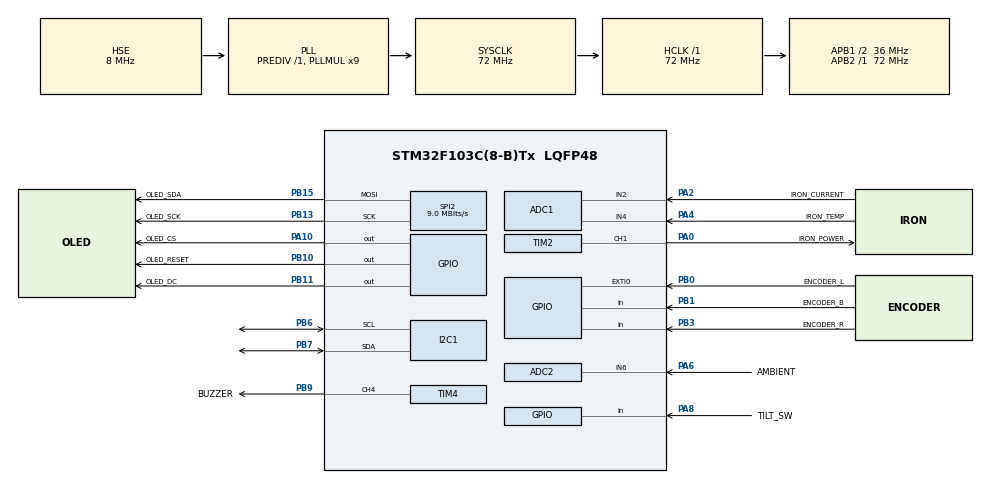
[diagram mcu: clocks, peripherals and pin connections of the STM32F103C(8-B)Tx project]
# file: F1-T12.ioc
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ADC1.Channel-0\#ChannelRegularConversion=ADC_CHANNEL_2
ADC1.Channel-1\#ChannelRegularConversion=ADC_CHANNEL_6
ADC1.ContinuousConvMode=ENABLE
ADC1.Mode=ADC_DUALMODE_INTERLFAST
ADC1.NbrOfConversion=2
ADC1.NbrOfConversionFlag=1
ADC1.Rank-0\#ChannelRegularConversion=1
ADC1.Rank-1\#ChannelRegularConversion=2
ADC1.SamplingTime-0\#ChannelRegularConversion=ADC_SAMPLETIME_71CYCLES_5
ADC1.SamplingTime-1\#ChannelRegularConversion=ADC_SAMPLETIME_71CYCLES_5
ADC1.master=1
ADC2.Channel-0\#ChannelRegularConversion=ADC_CHANNEL_4
ADC2.Channel-1\#ChannelRegularConversion=ADC_CHANNEL_4
ADC2.ContinuousConvMode=ENABLE
ADC2.Mode=ADC_DUALMODE_INTERLFAST
ADC2.NbrOfConversion=2
ADC2.NbrOfConversionFlag=1
ADC2.Rank-0\#ChannelRegularConversion=1
ADC2.Rank-1\#ChannelRegularConversion=2
ADC2.SamplingTime-0\#ChannelRegularConversion=ADC_SAMPLETIME_71CYCLES_5
ADC2.SamplingTime-1\#ChannelRegularConversion=ADC_SAMPLETIME_71CYCLES_5
Dma.ADC1.0.Direction=DMA_PERIPH_TO_MEMORY
Dma.ADC1.0.Instance=DMA1_Channel1
Dma.ADC1.0.MemDataAlignment=DMA_MDATAALIGN_WORD
Dma.ADC1.0.MemInc=DMA_MINC_ENABLE
Dma.ADC1.0.Mode=DMA_NORMAL
Dma.ADC1.0.PeriphDataAlignment=DMA_PDATAALIGN_WORD
Dma.ADC1.0.PeriphInc=DMA_PINC_DISABLE
Dma.ADC1.0.Priority=DMA_PRIORITY_LOW
Dma.Request0=ADC1
I2C1.I2C_Mode=I2C_Fast
Mcu.Family=STM32F1
Mcu.Name=STM32F103C(8-B)Tx
Mcu.Package=LQFP48
NVIC.DMA1_Channel1_IRQn=true\:0\:0\:false\:false\:true\:false\:true
NVIC.EXTI0_IRQn=true\:0\:0\:false\:false\:false\:true\:true
NVIC.PriorityGroup=NVIC_PRIORITYGROUP_4
NVIC.TIM2_IRQn=true\:0\:0\:false\:false\:true\:true\:true
PA0-WKUP.GPIO_Label=IRON_POWER
PA0-WKUP.Signal=S_TIM2_CH1_ETR
PA10.GPIO_Label=OLED_CS
PA10.Signal=GPIO_Output
PA13.Mode=Serial_Wire
PA13.Signal=SYS_JTMS-SWDIO
PA14.Mode=Serial_Wire
PA14.Signal=SYS_JTCK-SWCLK
PA2.GPIO_Label=IRON_CURRENT
PA2.Signal=ADCx_IN2
PA4.GPIO_Label=IRON_TEMP
PA4.Signal=ADCx_IN4
PA6.GPIO_Label=AMBIENT
PA6.Signal=ADCx_IN6
PA8.GPIO_Label=TILT_SW
PA8.GPIO_PuPd=GPIO_NOPULL
PA8.Signal=GPIO_Input
PB0.GPIO_Label=ENCODER_L
PB0.GPIO_ModeDefaultEXTI=GPIO_MODE_IT_RISING_FALLING
PB0.GPIO_PuPd=GPIO_PULLUP
PB0.Signal=GPXTI0
PB1.GPIO_Label=ENCODER_B
PB1.GPIO_PuPd=GPIO_PULLUP
PB1.Signal=GPIO_Input
PB10.GPIO_Label=OLED_RESET
PB10.Signal=GPIO_Output
PB11.GPIO_Label=OLED_DC
PB11.Signal=GPIO_Output
PB13.GPIO_Label=OLED_SCK
PB13.Mode=TX_Only_Simplex_Unidirect_Master
PB13.Signal=SPI2_SCK
PB15.GPIO_Label=OLED_SDA
PB15.Mode=TX_Only_Simplex_Unidirect_Master
PB15.Signal=SPI2_MOSI
PB3.GPIO_Label=ENCODER_R
PB3.GPIO_PuPd=GPIO_PULLUP
PB3.Signal=GPIO_Input
PB6.Mode=I2C
PB6.Signal=I2C1_SCL
PB7.Mode=I2C
PB7.Signal=I2C1_SDA
PB9.GPIO_Label=BUZZER
PB9.Signal=S_TIM4_CH4
PD0-OSC_IN.Mode=HSE-External-Oscillator
PD0-OSC_IN.Signal=RCC_OSC_IN
PD1-OSC_OUT.Mode=HSE-External-Oscillator
PD1-OSC_OUT.Signal=RCC_OSC_OUT
ProjectManager.HeapSize=0x200
ProjectManager.StackSize=0x400
ProjectManager.TargetToolchain=SW4STM32
RCC.ADCPresc=RCC_ADCPCLK2_DIV6
RCC.AHBFreq_Value=72000000
RCC.APB1CLKDivider=RCC_HCLK_DIV2
RCC.APB1Freq_Value=36000000
RCC.APB1TimFreq_Value=72000000
RCC.APB2Freq_Value=72000000
RCC.APB2TimFreq_Value=72000000
RCC.HCLKFreq_Value=72000000
RCC.PLLMUL=RCC_PLL_MUL9
RCC.PLLSourceVirtual=RCC_PLLSOURCE_HSE
RCC.SYSCLKFreq_VALUE=72000000
RCC.SYSCLKSource=RCC_SYSCLKSOURCE_PLLCLK
RCC.USBFreq_Value=72000000
SH.ADCx_IN2.0=ADC1_IN2,IN2
SH.ADCx_IN2.1=ADC2_IN2,IN2
SH.ADCx_IN4.0=ADC1_IN4,IN4
SH.ADCx_IN4.1=ADC2_IN4,IN4
SH.ADCx_IN6.0=ADC2_IN6,IN6
SH.ADCx_IN6.1=ADC1_IN6,IN6
SH.S_TIM2_CH1_ETR.0=TIM2_CH1,PWM Generation1 CH1
SH.S_TIM4_CH4.0=TIM4_CH4,PWM Generation4 CH4
SPI2.BaudRatePrescaler=SPI_BAUDRATEPRESCALER_4
SPI2.CalculateBaudRate=9.0 MBits/s
SPI2.Direction=SPI_DIRECTION_2LINES
SPI2.Mode=SPI_MODE_MASTER
SPI2.VirtualType=VM_MASTER
TIM2.Channel-Output\ Compare3\ No\ Output=TIM_CHANNEL_3
TIM2.Channel-Output\ Compare4\ No\ Output=TIM_CHANNEL_4
TIM2.Channel-PWM\ Generation1\ CH1=TIM_CHANNEL_1
TIM2.Period=1999
TIM2.Prescaler=749
TIM2.Pulse-Output\ Compare3\ No\ Output=1
TIM2.Pulse-Output\ Compare4\ No\ Output=1980
TIM2.Pulse-PWM\ Generation1\ CH1=0
TIM4.Channel-PWM\ Generation4\ CH4=TIM_CHANNEL_4
TIM4.OCPolarity_4=TIM_OCPOLARITY_LOW
TIM4.Period=65535
TIM4.Prescaler=71
TIM4.Pulse-PWM\ Generation4\ CH4=0
VP_TIM2_VS_ClockSourceINT.Mode=Internal
VP_TIM2_VS_no_output3.Mode=Output Compare3 No Output
VP_TIM2_VS_no_output4.Mode=Output Compare4 No Output
VP_TIM4_VS_ClockSourceINT.Mode=Internal
board=F1_OLED_SPI

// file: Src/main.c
/* USER CODE BEGIN Header */
/**
  ******************************************************************************
  * @file           : main.c
  * @brief          : Main program body
  ******************************************************************************
  * @attention
  *
  * <h2><center>&copy; Copyright (c) 2019 STMicroelectronics.
  * All rights reserved.</center></h2>
  *
  * This software component is licensed by ST under BSD 3-Clause license,
  * the "License"; You may not use this file except in compliance with the
  * License. You may obtain a copy of the License at:
  *                        opensource.org/licenses/BSD-3-Clause
  *
  ******************************************************************************
  */
/* USER CODE END Header */

#include "main.h"

/* USER CODE BEGIN Includes */
#include "core.h"

/* USER CODE END Includes */

ADC_HandleTypeDef hadc1;
ADC_HandleTypeDef hadc2;
DMA_HandleTypeDef hdma_adc1;

I2C_HandleTypeDef hi2c1;

SPI_HandleTypeDef hspi2;

TIM_HandleTypeDef htim2;
TIM_HandleTypeDef htim4;

void SystemClock_Config(void);
static void MX_GPIO_Init(void);
static void MX_DMA_Init(void);
static void MX_SPI2_Init(void);
static void MX_ADC1_Init(void);
static void MX_ADC2_Init(void);
static void MX_I2C1_Init(void);
static void MX_TIM2_Init(void);
static void MX_TIM4_Init(void);

int main(void)
{

  /* MCU Configuration--------------------------------------------------------*/

  /* Reset of all peripherals, Initializes the Flash interface and the Systick. */
  HAL_Init();

  /* Configure the system clock */
  SystemClock_Config();

  /* Initialize all configured peripherals */
  MX_GPIO_Init();
  MX_DMA_Init();
  MX_SPI2_Init();
  MX_ADC1_Init();
  MX_ADC2_Init();
  MX_I2C1_Init();
  MX_TIM2_Init();
  MX_TIM4_Init();
  /* USER CODE BEGIN 2 */
	HAL_TIM_PWM_Start(&htim4,    TIM_CHANNEL_4);			// PWM signal for the buzzer
  setup();

  /* USER CODE END 2 */

  /* Infinite loop */
  while (1)
  {

    /* USER CODE BEGIN 3 */
	  loop();
  }
  /* USER CODE END 3 */
}

void SystemClock_Config(void)
{
  RCC_OscInitTypeDef RCC_OscInitStruct = {0};
  RCC_ClkInitTypeDef RCC_ClkInitStruct = {0};
  RCC_PeriphCLKInitTypeDef PeriphClkInit = {0};

  /** Initializes the CPU, AHB and APB busses clocks
  */
  RCC_OscInitStruct.OscillatorType = RCC_OSCILLATORTYPE_HSE;
  RCC_OscInitStruct.HSEState = RCC_HSE_ON;
  RCC_OscInitStruct.HSEPredivValue = RCC_HSE_PREDIV_DIV1;
  RCC_OscInitStruct.HSIState = RCC_HSI_ON;
  RCC_OscInitStruct.PLL.PLLState = RCC_PLL_ON;
  RCC_OscInitStruct.PLL.PLLSource = RCC_PLLSOURCE_HSE;
  RCC_OscInitStruct.PLL.PLLMUL = RCC_PLL_MUL9;
  if (HAL_RCC_OscConfig(&RCC_OscInitStruct) != HAL_OK)
  {
    Error_Handler();
  }
  /** Initializes the CPU, AHB and APB busses clocks
  */
  RCC_ClkInitStruct.ClockType = RCC_CLOCKTYPE_HCLK|RCC_CLOCKTYPE_SYSCLK
                              |RCC_CLOCKTYPE_PCLK1|RCC_CLOCKTYPE_PCLK2;
  RCC_ClkInitStruct.SYSCLKSource = RCC_SYSCLKSOURCE_PLLCLK;
  RCC_ClkInitStruct.AHBCLKDivider = RCC_SYSCLK_DIV1;
  RCC_ClkInitStruct.APB1CLKDivider = RCC_HCLK_DIV2;
  RCC_ClkInitStruct.APB2CLKDivider = RCC_HCLK_DIV1;

  if (HAL_RCC_ClockConfig(&RCC_ClkInitStruct, FLASH_LATENCY_2) != HAL_OK)
  {
    Error_Handler();
  }
  PeriphClkInit.PeriphClockSelection = RCC_PERIPHCLK_ADC;
  PeriphClkInit.AdcClockSelection = RCC_ADCPCLK2_DIV6;
  if (HAL_RCCEx_PeriphCLKConfig(&PeriphClkInit) != HAL_OK)
  {
    Error_Handler();
  }
}

static void MX_ADC1_Init(void)
{

  ADC_MultiModeTypeDef multimode = {0};
  ADC_ChannelConfTypeDef sConfig = {0};

  /** Common config
  */
  hadc1.Instance = ADC1;
  hadc1.Init.ScanConvMode = ADC_SCAN_ENABLE;
  hadc1.Init.ContinuousConvMode = ENABLE;
  hadc1.Init.DiscontinuousConvMode = DISABLE;
  hadc1.Init.ExternalTrigConv = ADC_SOFTWARE_START;
  hadc1.Init.DataAlign = ADC_DATAALIGN_RIGHT;
  hadc1.Init.NbrOfConversion = 2;
  if (HAL_ADC_Init(&hadc1) != HAL_OK)
  {
    Error_Handler();
  }
  /** Configure the ADC multi-mode
  */
  multimode.Mode = ADC_DUALMODE_INTERLFAST;
  if (HAL_ADCEx_MultiModeConfigChannel(&hadc1, &multimode) != HAL_OK)
  {
    Error_Handler();
  }
  /** Configure Regular Channel
  */
  sConfig.Channel = ADC_CHANNEL_2;
  sConfig.Rank = ADC_REGULAR_RANK_1;
  sConfig.SamplingTime = ADC_SAMPLETIME_71CYCLES_5;
  if (HAL_ADC_ConfigChannel(&hadc1, &sConfig) != HAL_OK)
  {
    Error_Handler();
  }
  /** Configure Regular Channel
  */
  sConfig.Channel = ADC_CHANNEL_6;
  sConfig.Rank = ADC_REGULAR_RANK_2;
  if (HAL_ADC_ConfigChannel(&hadc1, &sConfig) != HAL_OK)
  {
    Error_Handler();
  }

}

static void MX_ADC2_Init(void)
{

  ADC_ChannelConfTypeDef sConfig = {0};

  /** Common config
  */
  hadc2.Instance = ADC2;
  hadc2.Init.ScanConvMode = ADC_SCAN_ENABLE;
  hadc2.Init.ContinuousConvMode = ENABLE;
  hadc2.Init.DiscontinuousConvMode = DISABLE;
  hadc2.Init.ExternalTrigConv = ADC_SOFTWARE_START;
  hadc2.Init.DataAlign = ADC_DATAALIGN_RIGHT;
  hadc2.Init.NbrOfConversion = 2;
  if (HAL_ADC_Init(&hadc2) != HAL_OK)
  {
    Error_Handler();
  }
  /** Configure Regular Channel
  */
  sConfig.Channel = ADC_CHANNEL_4;
  sConfig.Rank = ADC_REGULAR_RANK_1;
  sConfig.SamplingTime = ADC_SAMPLETIME_71CYCLES_5;
  if (HAL_ADC_ConfigChannel(&hadc2, &sConfig) != HAL_OK)
  {
    Error_Handler();
  }
  /** Configure Regular Channel
  */
  sConfig.Rank = ADC_REGULAR_RANK_2;
  if (HAL_ADC_ConfigChannel(&hadc2, &sConfig) != HAL_OK)
  {
    Error_Handler();
  }

}

static void MX_I2C1_Init(void)
{

  hi2c1.Instance = I2C1;
  hi2c1.Init.ClockSpeed = 400000;
  hi2c1.Init.DutyCycle = I2C_DUTYCYCLE_2;
  hi2c1.Init.OwnAddress1 = 0;
  hi2c1.Init.AddressingMode = I2C_ADDRESSINGMODE_7BIT;
  hi2c1.Init.DualAddressMode = I2C_DUALADDRESS_DISABLE;
  hi2c1.Init.OwnAddress2 = 0;
  hi2c1.Init.GeneralCallMode = I2C_GENERALCALL_DISABLE;
  hi2c1.Init.NoStretchMode = I2C_NOSTRETCH_DISABLE;
  if (HAL_I2C_Init(&hi2c1) != HAL_OK)
  {
    Error_Handler();
  }

}

static void MX_SPI2_Init(void)
{

  /* SPI2 parameter configuration*/
  hspi2.Instance = SPI2;
  hspi2.Init.Mode = SPI_MODE_MASTER;
  hspi2.Init.Direction = SPI_DIRECTION_2LINES;
  hspi2.Init.DataSize = SPI_DATASIZE_8BIT;
  hspi2.Init.CLKPolarity = SPI_POLARITY_LOW;
  hspi2.Init.CLKPhase = SPI_PHASE_1EDGE;
  hspi2.Init.NSS = SPI_NSS_SOFT;
  hspi2.Init.BaudRatePrescaler = SPI_BAUDRATEPRESCALER_4;
  hspi2.Init.FirstBit = SPI_FIRSTBIT_MSB;
  hspi2.Init.TIMode = SPI_TIMODE_DISABLE;
  hspi2.Init.CRCCalculation = SPI_CRCCALCULATION_DISABLE;
  hspi2.Init.CRCPolynomial = 10;
  if (HAL_SPI_Init(&hspi2) != HAL_OK)
  {
    Error_Handler();
  }

}

static void MX_TIM2_Init(void)
{

  TIM_ClockConfigTypeDef sClockSourceConfig = {0};
  TIM_MasterConfigTypeDef sMasterConfig = {0};
  TIM_OC_InitTypeDef sConfigOC = {0};

  htim2.Instance = TIM2;
  htim2.Init.Prescaler = 749;
  htim2.Init.CounterMode = TIM_COUNTERMODE_UP;
  htim2.Init.Period = 1999;
  htim2.Init.ClockDivision = TIM_CLOCKDIVISION_DIV1;
  htim2.Init.AutoReloadPreload = TIM_AUTORELOAD_PRELOAD_DISABLE;
  if (HAL_TIM_Base_Init(&htim2) != HAL_OK)
  {
    Error_Handler();
  }
  sClockSourceConfig.ClockSource = TIM_CLOCKSOURCE_INTERNAL;
  if (HAL_TIM_ConfigClockSource(&htim2, &sClockSourceConfig) != HAL_OK)
  {
    Error_Handler();
  }
  if (HAL_TIM_PWM_Init(&htim2) != HAL_OK)
  {
    Error_Handler();
  }
  if (HAL_TIM_OC_Init(&htim2) != HAL_OK)
  {
    Error_Handler();
  }
  sMasterConfig.MasterOutputTrigger = TIM_TRGO_RESET;
  sMasterConfig.MasterSlaveMode = TIM_MASTERSLAVEMODE_DISABLE;
  if (HAL_TIMEx_MasterConfigSynchronization(&htim2, &sMasterConfig) != HAL_OK)
  {
    Error_Handler();
  }
  sConfigOC.OCMode = TIM_OCMODE_PWM1;
  sConfigOC.Pulse = 0;
  sConfigOC.OCPolarity = TIM_OCPOLARITY_HIGH;
  sConfigOC.OCFastMode = TIM_OCFAST_DISABLE;
  if (HAL_TIM_PWM_ConfigChannel(&htim2, &sConfigOC, TIM_CHANNEL_1) != HAL_OK)
  {
    Error_Handler();
  }
  sConfigOC.OCMode = TIM_OCMODE_TIMING;
  sConfigOC.Pulse = 1;
  if (HAL_TIM_OC_ConfigChannel(&htim2, &sConfigOC, TIM_CHANNEL_3) != HAL_OK)
  {
    Error_Handler();
  }
  sConfigOC.Pulse = 1980;
  if (HAL_TIM_OC_ConfigChannel(&htim2, &sConfigOC, TIM_CHANNEL_4) != HAL_OK)
  {
    Error_Handler();
  }
  HAL_TIM_MspPostInit(&htim2);

}

static void MX_TIM4_Init(void)
{

  TIM_ClockConfigTypeDef sClockSourceConfig = {0};
  TIM_MasterConfigTypeDef sMasterConfig = {0};
  TIM_OC_InitTypeDef sConfigOC = {0};

  htim4.Instance = TIM4;
  htim4.Init.Prescaler = 71;
  htim4.Init.CounterMode = TIM_COUNTERMODE_UP;
  htim4.Init.Period = 65535;
  htim4.Init.ClockDivision = TIM_CLOCKDIVISION_DIV1;
  htim4.Init.AutoReloadPreload = TIM_AUTORELOAD_PRELOAD_DISABLE;
  if (HAL_TIM_Base_Init(&htim4) != HAL_OK)
  {
    Error_Handler();
  }
  sClockSourceConfig.ClockSource = TIM_CLOCKSOURCE_INTERNAL;
  if (HAL_TIM_ConfigClockSource(&htim4, &sClockSourceConfig) != HAL_OK)
  {
    Error_Handler();
  }
  if (HAL_TIM_PWM_Init(&htim4) != HAL_OK)
  {
    Error_Handler();
  }
  sMasterConfig.MasterOutputTrigger = TIM_TRGO_RESET;
  sMasterConfig.MasterSlaveMode = TIM_MASTERSLAVEMODE_DISABLE;
  if (HAL_TIMEx_MasterConfigSynchronization(&htim4, &sMasterConfig) != HAL_OK)
  {
    Error_Handler();
  }
  sConfigOC.OCMode = TIM_OCMODE_PWM1;
  sConfigOC.Pulse = 0;
  sConfigOC.OCPolarity = TIM_OCPOLARITY_LOW;
  sConfigOC.OCFastMode = TIM_OCFAST_DISABLE;
  if (HAL_TIM_PWM_ConfigChannel(&htim4, &sConfigOC, TIM_CHANNEL_4) != HAL_OK)
  {
    Error_Handler();
  }
  HAL_TIM_MspPostInit(&htim4);

}

static void MX_DMA_Init(void)
{

  /* DMA controller clock enable */
  __HAL_RCC_DMA1_CLK_ENABLE();

  /* DMA interrupt init */
  /* DMA1_Channel1_IRQn interrupt configuration */
  HAL_NVIC_SetPriority(DMA1_Channel1_IRQn, 0, 0);
  HAL_NVIC_EnableIRQ(DMA1_Channel1_IRQn);

}

static void MX_GPIO_Init(void)
{
  GPIO_InitTypeDef GPIO_InitStruct = {0};

  /* GPIO Ports Clock Enable */
  __HAL_RCC_GPIOD_CLK_ENABLE();
  __HAL_RCC_GPIOA_CLK_ENABLE();
  __HAL_RCC_GPIOB_CLK_ENABLE();

  /*Configure GPIO pin Output Level */
  HAL_GPIO_WritePin(GPIOB, OLED_RESET_Pin|OLED_DC_Pin, GPIO_PIN_RESET);

  /*Configure GPIO pin Output Level */
  HAL_GPIO_WritePin(OLED_CS_GPIO_Port, OLED_CS_Pin, GPIO_PIN_RESET);

  /*Configure GPIO pin : ENCODER_L_Pin */
  GPIO_InitStruct.Pin = ENCODER_L_Pin;
  GPIO_InitStruct.Mode = GPIO_MODE_IT_RISING_FALLING;
  GPIO_InitStruct.Pull = GPIO_PULLUP;
  HAL_GPIO_Init(ENCODER_L_GPIO_Port, &GPIO_InitStruct);

  /*Configure GPIO pins : ENCODER_B_Pin ENCODER_R_Pin */
  GPIO_InitStruct.Pin = ENCODER_B_Pin|ENCODER_R_Pin;
  GPIO_InitStruct.Mode = GPIO_MODE_INPUT;
  GPIO_InitStruct.Pull = GPIO_PULLUP;
  HAL_GPIO_Init(GPIOB, &GPIO_InitStruct);

  /*Configure GPIO pins : OLED_RESET_Pin OLED_DC_Pin */
  GPIO_InitStruct.Pin = OLED_RESET_Pin|OLED_DC_Pin;
  GPIO_InitStruct.Mode = GPIO_MODE_OUTPUT_PP;
  GPIO_InitStruct.Pull = GPIO_NOPULL;
  GPIO_InitStruct.Speed = GPIO_SPEED_FREQ_LOW;
  HAL_GPIO_Init(GPIOB, &GPIO_InitStruct);

  /*Configure GPIO pin : TILT_SW_Pin */
  GPIO_InitStruct.Pin = TILT_SW_Pin;
  GPIO_InitStruct.Mode = GPIO_MODE_INPUT;
  GPIO_InitStruct.Pull = GPIO_NOPULL;
  HAL_GPIO_Init(TILT_SW_GPIO_Port, &GPIO_InitStruct);

  /*Configure GPIO pin : OLED_CS_Pin */
  GPIO_InitStruct.Pin = OLED_CS_Pin;
  GPIO_InitStruct.Mode = GPIO_MODE_OUTPUT_PP;
  GPIO_InitStruct.Pull = GPIO_NOPULL;
  GPIO_InitStruct.Speed = GPIO_SPEED_FREQ_LOW;
  HAL_GPIO_Init(OLED_CS_GPIO_Port, &GPIO_InitStruct);

  /* EXTI interrupt init*/
  HAL_NVIC_SetPriority(EXTI0_IRQn, 0, 0);
  HAL_NVIC_EnableIRQ(EXTI0_IRQn);

}

void Error_Handler(void)
{
}

/************************ (C) COPYRIGHT STMicroelectronics *****END OF FILE****/
